# STM32WLE5_CM4 register map
File version: 1.0
CPU: CM4 r0p1, little endian, MPU, FPU, 4 interrupt priority bits
Registers are 32-bit, read-write, reset 0x0 unless marked. A register's access mark holds for its fields unless they carry their own. Offsets are from the block's base; [hi:lo] are bit positions; {n}, {i} and the like mark numbered series.

## LPUART — Universal synchronous asynchronous receiver transmitter
Base 0x40008000
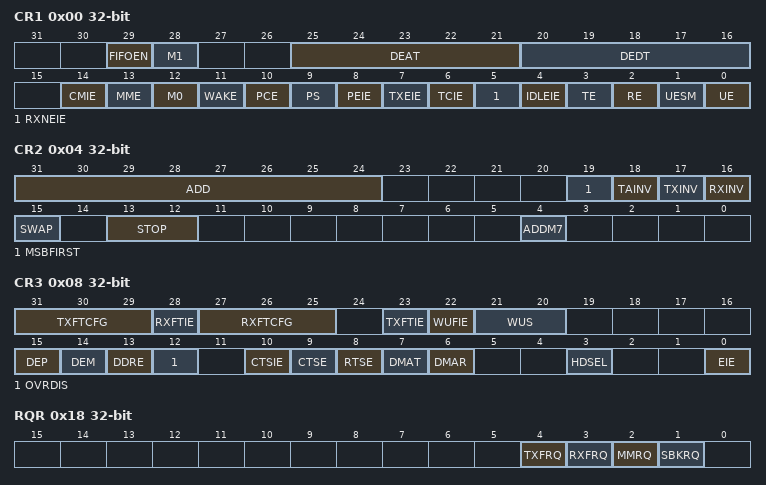
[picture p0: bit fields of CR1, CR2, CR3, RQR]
0x00 CR1 — Control register 1
  [29] FIFOEN — FIFO mode enable
  [28] M1 — Word length
  [25:21] DEAT
  [20:16] DEDT
  [14] CMIE — Character match interrupt enable
  [13] MME — Mute mode enable
  [12] M0 — Word length
  [11] WAKE — Receiver wakeup method
  [10] PCE — Parity control enable
  [9] PS — Parity selection
  [8] PEIE — PE interrupt enable
  [7] TXEIE — interrupt enable
  [6] TCIE — Transmission complete interrupt enable
  [5] RXNEIE — RXNE interrupt enable
  [4] IDLEIE — IDLE interrupt enable
  [3] TE — Transmitter enable
  [2] RE — Receiver enable
  [1] UESM — USART enable in Stop mode
  [0] UE — USART enable
0x04 CR2 — Control register 2
  [31:24] ADD — Address of the USART node
  [19] MSBFIRST — Most significant bit first
  [18] TAINV — Binary data inversion
  [17] TXINV — TX pin active level inversion
  [16] RXINV — RX pin active level inversion
  [15] SWAP — Swap TX/RX pins
  [13:12] STOP — STOP bits
  [4] ADDM7 — 7-bit Address Detection/4-bit Address Detection
0x08 CR3 — Control register 3
  [31:29] TXFTCFG — TXFIFO threshold configuration
  [28] RXFTIE — RXFIFO threshold interrupt enable
  [27:25] RXFTCFG — Receive FIFO threshold configuration
  [23] TXFTIE — threshold interrupt enable
  [22] WUFIE — Wakeup from Stop mode interrupt enable
  [21:20] WUS — Wakeup from Stop mode interrupt flag selection
  [15] DEP — Driver enable polarity selection
  [14] DEM — Driver enable mode
  [13] DDRE — DMA Disable on Reception Error
  [12] OVRDIS — Overrun Disable
  [10] CTSIE — CTS interrupt enable
  [9] CTSE — CTS enable
  [8] RTSE — RTS enable
  [7] DMAT — DMA enable transmitter
  [6] DMAR — DMA enable receiver
  [3] HDSEL — Half-duplex selection
  [0] EIE — Error interrupt enable
0x0C BRR — Baud rate register
  [19:0] BRR
0x18 RQR wo — Request register
  [4] TXFRQ — Transmit data flush request
  [3] RXFRQ — Receive data flush request
  [2] MMRQ — Mute mode request
  [1] SBKRQ — Send break request
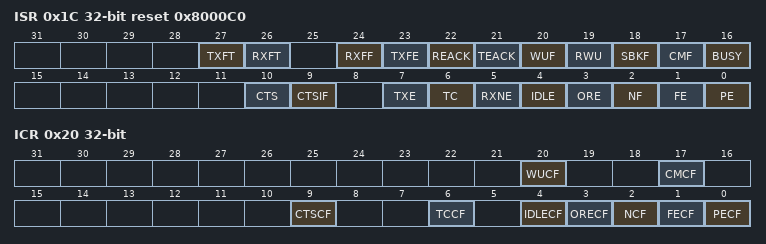
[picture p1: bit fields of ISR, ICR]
0x1C ISR ro reset 0x8000C0 — Interrupt & status register
  [27] TXFT — TXFIFO threshold flag
  [26] RXFT — RXFIFO threshold flag
  [24] RXFF — RXFIFO Full
  [23] TXFE — TXFIFO Empty
  [22] REACK
  [21] TEACK
  [20] WUF
  [19] RWU
  [18] SBKF
  [17] CMF
  [16] BUSY
  [10] CTS
  [9] CTSIF
  [7] TXE
  [6] TC
  [5] RXNE
  [4] IDLE
  [3] ORE
  [2] NF
  [1] FE
  [0] PE
0x20 ICR wo — Interrupt flag clear register
  [20] WUCF — Wakeup from Stop mode clear flag
  [17] CMCF — Character match clear flag
  [9] CTSCF — CTS clear flag
  [6] TCCF — Transmission complete clear flag
  [4] IDLECF — Idle line detected clear flag
  [3] ORECF — Overrun error clear flag
  [2] NCF — Noise detected clear flag
  [1] FECF — Framing error clear flag
  [0] PECF — Parity error clear flag
0x24 RDR ro — Receive data register
  [8:0] RDR — Receive data value
0x28 TDR — Transmit data register
  [8:0] TDR — Transmit data value
0x2C PRESC — Prescaler register
  [3:0] PRESCALER — Clock prescaler

## TAMP — Tamper and backup registers
Base 0x4000B000
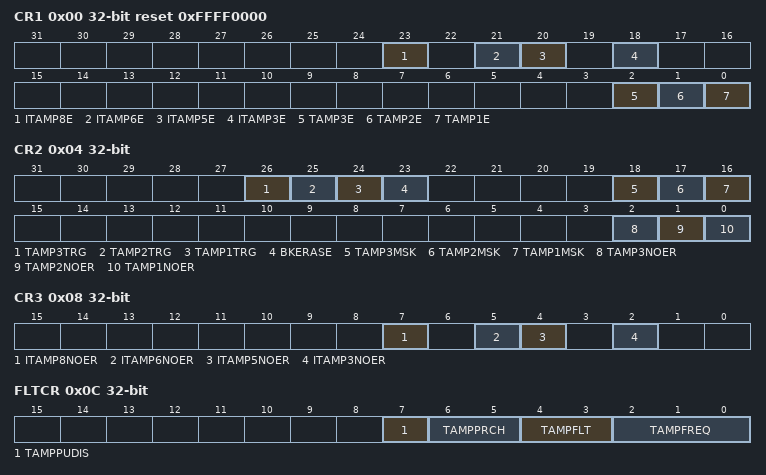
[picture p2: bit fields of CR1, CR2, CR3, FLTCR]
0x00 CR1 reset 0xFFFF0000 — control register 1
  [23] ITAMP8E
  [21] ITAMP6E
  [20] ITAMP5E
  [18] ITAMP3E
  [2] TAMP3E — TAMP2E
  [1] TAMP2E
  [0] TAMP1E
0x04 CR2 — control register 2
  [26] TAMP3TRG
  [25] TAMP2TRG
  [24] TAMP1TRG
  [23] BKERASE — Backup registerserase
  [18] TAMP3MSK
  [17] TAMP2MSK
  [16] TAMP1MSK
  [2] TAMP3NOER
  [1] TAMP2NOER
  [0] TAMP1NOER
0x08 CR3 — TAMP control register 3
  [7] ITAMP8NOER, [5] ITAMP6NOER, [4] ITAMP5NOER, [2] ITAMP3NOER
0x0C FLTCR — TAMP filter control register
  [7] TAMPPUDIS, [6:5] TAMPPRCH, [4:3] TAMPFLT, [2:0] TAMPFREQ
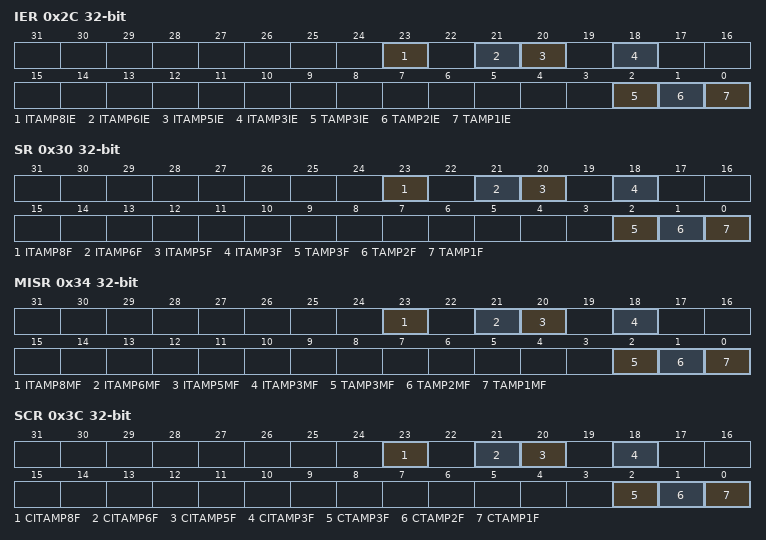
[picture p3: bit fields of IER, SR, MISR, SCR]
0x2C IER — TAMP interrupt enable register
  [23] ITAMP8IE, [21] ITAMP6IE, [20] ITAMP5IE, [18] ITAMP3IE, [2] TAMP3IE, [1] TAMP2IE, [0] TAMP1IE
0x30 SR ro — TAMP status register
  [23] ITAMP8F, [21] ITAMP6F, [20] ITAMP5F, [18] ITAMP3F, [2] TAMP3F, [1] TAMP2F, [0] TAMP1F
0x34 MISR ro — TAMP masked interrupt status register
  [23] ITAMP8MF, [21] ITAMP6MF, [20] ITAMP5MF, [18] ITAMP3MF, [2] TAMP3MF, [1] TAMP2MF, [0] TAMP1MF
0x3C SCR wo — TAMP status clear register
  [23] CITAMP8F, [21] CITAMP6F, [20] CITAMP5F, [18] CITAMP3F, [2] CTAMP3F, [1] CTAMP2F, [0] CTAMP1F
0x40 COUNTR ro — monotonic counter register
  [31:0] COUNT
{0x100+4i} BKP{i}R (i=0..9) — TAMP backup register
  [31:0] BKP
{0x118+4i} BKP{i}R (i=10..19) — TAMP backup register
  [31:0] BKP
